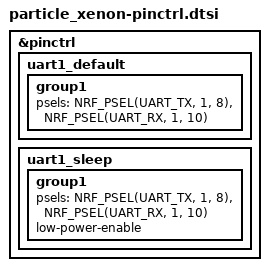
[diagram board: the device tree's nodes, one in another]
/*
 * Copyright (c) 2022 Nordic Semiconductor
 * SPDX-License-Identifier: Apache-2.0
 */

&pinctrl {
	uart1_default: uart1_default {
		group1 {
			psels = <NRF_PSEL(UART_TX, 1, 8)>,
				<NRF_PSEL(UART_RX, 1, 10)>;
		};
	};

	uart1_sleep: uart1_sleep {
		group1 {
			psels = <NRF_PSEL(UART_TX, 1, 8)>,
				<NRF_PSEL(UART_RX, 1, 10)>;
			low-power-enable;
		};
	};

};
